# S6E2DFxJ register map
Vendor: Cypress; File version: 2.1
CPU: CM4 r0p1, little endian, MPU, FPU, 4 interrupt priority bits
Registers are 32-bit, read-write, reset 0x0 unless marked. A register's access mark holds for its fields unless they carry their own. Offsets are from the block's base; [hi:lo] are bit positions; {n}, {i} and the like mark numbered series; 'fields as' and 'values as' point back to an identical list.

## FLASH_IF — Flash Memory
Base 0x40000000
0x00 FASZR reset 0x2 — Flash Access Size Register [BHW]
  [1:0] ASZ — Access Size
0x04 FRWTR reset 0x3 — Flash Read Wait Register [BHW]
  [1:0] RWT — Read Wait Cycle
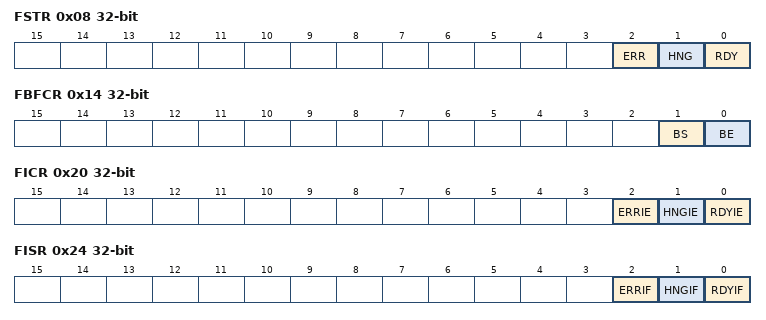
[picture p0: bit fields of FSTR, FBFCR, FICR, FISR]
0x08 FSTR — Flash Status Register [BHW]
  [2] ERR — Flash ECC Error
  [1] HNG ro — Flash Hang
  [0] RDY ro — Flash Rdy
0x10 FSYNDN — Flash Sync Down Register [BHW]
  [2:0] SD — Sync Down
0x14 FBFCR — Flash Buffer Control Register [BHW]
  [1] BS ro — Buffer Status
  [0] BE — Buffer Enable
0x20 FICR — Flash Interrupt Control Register [BHW]
  [2] ERRIE — Flash ECC Error Interrupt Enable
  [1] HNGIE — Flash HANG Interrupt Enable
  [0] RDYIE — Flash RDY Interrupt Enable
0x24 FISR ro — Flash Interrupt Status Register [BHW]
  [2] ERRIF — Flash ECC Error Interrupt Flag
  [1] HNGIF — Flash HANG Interrupt Flag
  [0] RDYIF — Flash RDY Interrupt Flag
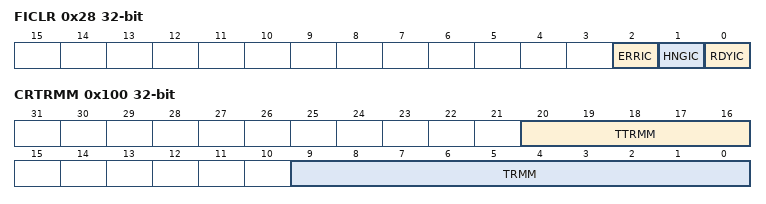
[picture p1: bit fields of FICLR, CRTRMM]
0x28 FICLR — Flash Interrupt Clear Register [BHW]
  [2] ERRIC — Flash ECC Error Interrupt Clear
  [1] HNGIC — Flash HANG Interrupt Clear
  [0] RDYIC — Flash RDY Interrupt Clear
0x100 CRTRMM ro — CR Trimming Data Mirror Register [BHW]
  [20:16] TTRMM — Temperature CR Trimming Data Mirror
  [9:0] TRMM — CR Trimming Data Mirror
{0x10C+4i} FGPDM{i} ro (i=1..4) — Flash General Purpose Data Mirror Register{i} [BHW]
  [31:0] GPD{i} — General Purpose Data{i}

## UNIQUE_ID
Base 0x40000200
0x00 UIDR0 ro reset not defined — Unique ID Register 0 [W]
  [31:4] UID — Unique ID 27 through 0
0x04 UIDR1 ro reset not defined — Unique ID Register 1 [W]
  [12:0] UID — Unique ID 40 through 28

## ECC_CAPTURE — ECC Capture Address
Base 0x40000300
0x00 FERRAD ro — Flash ECC Error Address Capture Register [W]
  [22:0] ERRAD — Flash ECC Error Address Capture

## HWWDT — Hardware Watchdog Timer
Base 0x40011000
0x00 WDG_LDR reset 0xFFFF — Hardware Watchdog Timer Load Register [W]
0x04 WDG_VLR ro reset 0xFFFF — Hardware Watchdog Timer Value Register [W]
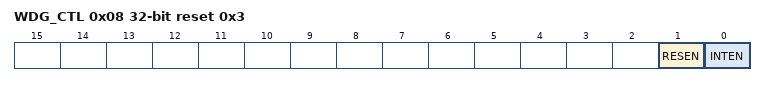
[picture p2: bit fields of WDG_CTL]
0x08 WDG_CTL reset 0x3 — Hardware Watchdog Timer Control Register [W]
  [1] RESEN — Hardware watchdog reset enable bit
  [0] INTEN — Hardware watchdog interrupt and counter enable bit
0x0C WDG_ICL reset not defined — Hardware Watchdog Timer Clear Register [W]
0x10 WDG_RIS ro — Hardware Watchdog Timer Interrupt Status Register [W]
  [0] RIS — Hardware watchdog interrupt status bit
0xC00 WDG_LCK reset 0x1 — Hardware Watchdog Timer Lock Register [W]

## SWWDT — Software Watchdog Timer
Base 0x40012000
0x00 WDOGLOAD reset 0xFFFFFFFF — Software Watchdog Timer Load Register [W]
0x04 WDOGVALUE ro reset 0xFFFFFFFF — Software Watchdog Timer Value Register [W]
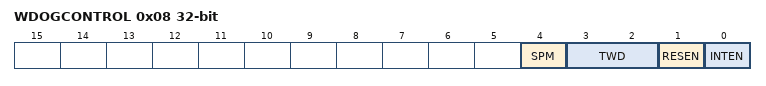
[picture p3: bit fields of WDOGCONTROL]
0x08 WDOGCONTROL — Software Watchdog Timer Control Register [W]
  [4] SPM — Software Watchdog window watchdog mode enable bit
  [3:2] TWD — Timing window setting bit of the software watchdog
  [1] RESEN — Reset enable bit of the software watchdog
  [0] INTEN — Interrupt and counter enable bit of the software watchdog
0x0C WDOGINTCLR reset not defined — Software Watchdog Timer Clear Register [W]
0x10 WDOGRIS ro — Software Watchdog Timer Interrupt Status Register [W]
  [0] RIS — Software watchdog interrupt status bit
0x18 WDOGSPMC — Software Watchdog Timer Window Watchdog Mode Control Register [W]
  [0] TGR — Software watchdog trigger type bit
0xC00 WDOGLOCK — Software Watchdog Timer Lock Register [W]

## DT — Dual Timer
Base 0x40015000
0x00 TIMER1LOAD — Load Register [W]
0x04 TIMER1VALUE ro reset 0xFFFFFFFF — Value Register [W]
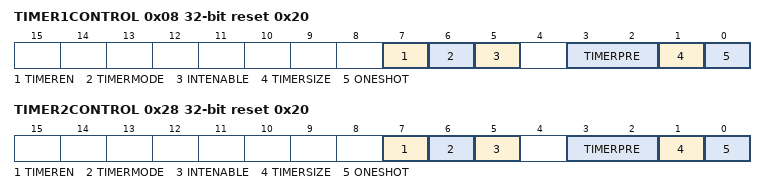
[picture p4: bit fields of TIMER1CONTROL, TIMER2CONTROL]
0x08 TIMER1CONTROL reset 0x20 — Control Register [W]
  [7] TIMEREN — Enable bit
  [6] TIMERMODE — Mode bit
  [5] INTENABLE — Interrupt enable bit
  [3:2] TIMERPRE — Prescale bits
  [1] TIMERSIZE — Counter size bit
  [0] ONESHOT — One-shot mode bit
0x0C TIMER1INTCLR wo reset not defined — Interrupt Clear Register [W]
0x10 TIMER1RIS ro — Interrupt Status Register [W]
  [0] TIMER1RIS — Interrupt Status Register bit
0x14 TIMER1MIS ro — Masked Interrupt Status Register [W]
  [0] TIMER1MIS — Masked Interrupt Status bit
0x18 TIMER1BGLOAD — Background Load Register [W]
0x20 TIMER2LOAD — Load Register [W]
0x24 TIMER2VALUE ro reset 0xFFFFFFFF — Value Register [W]
0x28 TIMER2CONTROL reset 0x20 — Control Register [W]
  fields as TIMER1CONTROL
0x2C TIMER2INTCLR wo reset not defined — Interrupt Clear Register [W]
0x30 TIMER2RIS ro — Interrupt Status Register [W]
  [0] TIMER2RIS — Interrupt Status Register bit
0x34 TIMER2MIS ro — Masked Interrupt Status Register [W]
  [0] TIMER2MIS — Masked Interrupt Status bit
0x38 TIMER2BGLOAD — Background Load Register [W]

## Notices in the file
Copyright (C) 2013-2016, Cypress Semiconductor Corporation or a
subsidiary of Cypress Semiconductor Corporation.  All rights reserved.
This software, including source code, documentation and related
materials ("Software"), is owned by Cypress Semiconductor Corporation or
one of its subsidiaries ("Cypress") and is protected by and subject to
worldwide patent protection (United States and foreign), United States
copyright laws and international treaty provisions. Therefore, you may use
this Software only as provided in the license agreement accompanying the
software package from which you obtained this Software ("EULA").
If no EULA applies, Cypress hereby grants you a personal, non-exclusive,
non-transferable license to copy, modify, and compile the
Software source code solely for use in connection with Cypress's
integrated circuit products.  Any reproduction, modification, translation,
compilation, or representation of this Software except as specified
above is prohibited without the express written permission of Cypress.
Disclaimer: THIS SOFTWARE IS PROVIDED AS-IS, WITH NO
WARRANTY OF ANY KIND, EXPRESS OR IMPLIED, INCLUDING,
BUT NOT LIMITED TO, NONINFRINGEMENT, IMPLIED
WARRANTIES OF MERCHANTABILITY AND FITNESS FOR A
PARTICULAR PURPOSE. Cypress reserves the right to make
changes to the Software without notice. Cypress does not assume any
liability arising out of the application or use of the Software or any
product or circuit described in the Software. Cypress does not
authorize its products for use in any products where a malfunction or
failure of the Cypress product may reasonably be expected to result in
significant property damage, injury or death ("High Risk Product"). By
including Cypress's product in a High Risk Product, the manufacturer
of such system or application assumes all risk of such use and in doing
so agrees to indemnify Cypress against all liability.
